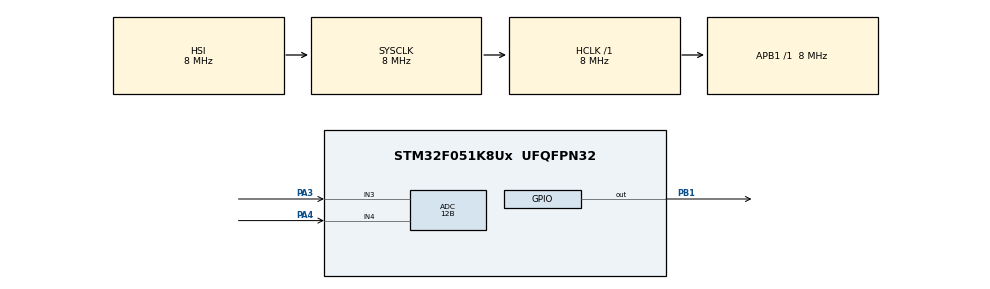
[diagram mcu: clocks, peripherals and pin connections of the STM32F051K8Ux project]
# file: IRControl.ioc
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ADC.ClockPrescaler=ADC_CLOCK_SYNC_PCLK_DIV4
ADC.ContinuousConvMode=DISABLE
ADC.DMAContinuousRequests=DISABLE
ADC.DataAlign=ADC_DATAALIGN_RIGHT
ADC.DiscontinuousConvMode=DISABLE
ADC.EOCSelection=ADC_EOC_SINGLE_CONV
ADC.EnableAnalogWatchDog=false
ADC.ExternalTrigConv=ADC_EXTERNALTRIGCONV_T2_TRGO
ADC.ExternalTrigConvEdge=ADC_EXTERNALTRIGCONVEDGE_RISING
ADC.LowPowerAutoPowerOff=DISABLE
ADC.LowPowerAutoWait=DISABLE
ADC.Overrun=ADC_OVR_DATA_OVERWRITTEN
ADC.Resolution=ADC_RESOLUTION_12B
ADC.SamplingTime=ADC_SAMPLETIME_28CYCLES_5
ADC.ScanConvMode=ADC_SCAN_DIRECTION_FORWARD
Mcu.Family=STM32F0
Mcu.Name=STM32F051K8Ux
Mcu.Package=UFQFPN32
NVIC.ADC1_COMP_IRQn=true\:0\:0\:false\:false\:true\:true
NVIC.TIM6_DAC_IRQn=true\:0\:0\:false\:false\:true\:true
PA13.Mode=Serial_Wire
PA13.Signal=SYS_SWDIO
PA14.Mode=Serial_Wire
PA14.Signal=SYS_SWCLK
PA3.Mode=IN3
PA3.Signal=ADC_IN3
PA4.Mode=IN4
PA4.Signal=ADC_IN4
PB1.Signal=GPIO_Output
ProjectManager.HeapSize=0x200
ProjectManager.StackSize=0x400
ProjectManager.TargetToolchain=EWARM
RCC.AHBFreq_Value=8000000
RCC.APB1Freq_Value=8000000
RCC.APB1TimFreq_Value=8000000
RCC.HCLKFreq_Value=8000000
RCC.PLLMUL=RCC_PLL_MUL9
RCC.SYSCLKFreq_VALUE=8000000
TIM2.TIM_MasterOutputTrigger=TIM_TRGO_UPDATE
VP_TIM2_VS_ClockSourceINT.Mode=Internal
VP_TIM6_VS_ClockSourceINT.Mode=Enable_Timer
board=IRControl

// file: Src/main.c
/**
  ******************************************************************************
  * File Name          : main.c
  * Description        : Main program body
  ******************************************************************************
  ** This notice applies to any and all portions of this file
  * that are not between comment pairs USER CODE BEGIN and
  * USER CODE END. Other portions of this file, whether
  * inserted by the user or by software development tools
  * are owned by their respective copyright owners.
  *
  * COPYRIGHT(c) 2017 STMicroelectronics
  *
  * Redistribution and use in source and binary forms, with or without modification,
  * are permitted provided that the following conditions are met:
  *   1. Redistributions of source code must retain the above copyright notice,
  *      this list of conditions and the following disclaimer.
  *   2. Redistributions in binary form must reproduce the above copyright notice,
  *      this list of conditions and the following disclaimer in the documentation
  *      and/or other materials provided with the distribution.
  *   3. Neither the name of STMicroelectronics nor the names of its contributors
  *      may be used to endorse or promote products derived from this software
  *      without specific prior written permission.
  *
  * THIS SOFTWARE IS PROVIDED BY THE COPYRIGHT HOLDERS AND CONTRIBUTORS "AS IS"
  * AND ANY EXPRESS OR IMPLIED WARRANTIES, INCLUDING, BUT NOT LIMITED TO, THE
  * IMPLIED WARRANTIES OF MERCHANTABILITY AND FITNESS FOR A PARTICULAR PURPOSE ARE
  * DISCLAIMED. IN NO EVENT SHALL THE COPYRIGHT HOLDER OR CONTRIBUTORS BE LIABLE
  * FOR ANY DIRECT, INDIRECT, INCIDENTAL, SPECIAL, EXEMPLARY, OR CONSEQUENTIAL
  * DAMAGES (INCLUDING, BUT NOT LIMITED TO, PROCUREMENT OF SUBSTITUTE GOODS OR
  * SERVICES; LOSS OF USE, DATA, OR PROFITS; OR BUSINESS INTERRUPTION) HOWEVER
  * CAUSED AND ON ANY THEORY OF LIABILITY, WHETHER IN CONTRACT, STRICT LIABILITY,
  * OR TORT (INCLUDING NEGLIGENCE OR OTHERWISE) ARISING IN ANY WAY OUT OF THE USE
  * OF THIS SOFTWARE, EVEN IF ADVISED OF THE POSSIBILITY OF SUCH DAMAGE.
  *
  ******************************************************************************
  */

#include "main.h"
#include "stm32f0xx_hal.h"

/* USER CODE BEGIN Includes */
#define ADC_BUF_SIZE   ((uint32_t)  128)   /* Size of array aADCxConvertedData[] */

/* USER CODE END Includes */

ADC_HandleTypeDef hadc;

TIM_HandleTypeDef htim2;
TIM_HandleTypeDef htim6;

/* USER CODE BEGIN PV */
/* Private variables ---------------------------------------------------------*/
uint16_t Counts[NumCount];
uint8_t  flag_ovf;
static uint16_t   DataADCCh3[ADC_BUF_SIZE];
static uint16_t   DataADCCh4[ADC_BUF_SIZE];
//__IO uint16_t uhADCxConvertedValue = 0;
uint8_t IndADC3=0,IndADC4=0;

/* USER CODE END PV */

void SystemClock_Config(void);
static void MX_GPIO_Init(void);
static void MX_ADC_Init(void);
static void MX_TIM6_Init(void);
static void MX_TIM2_Init(void);

/* USER CODE BEGIN PFP */
/* Private function prototypes -----------------------------------------------*/
void TimeControlInit(void);
/* USER CODE END PFP */

int main(void)
{

  /* MCU Configuration----------------------------------------------------------*/

  /* Reset of all peripherals, Initializes the Flash interface and the Systick. */
  HAL_Init();

  /* Configure the system clock */
  SystemClock_Config();

  /* Initialize all configured peripherals */
  MX_GPIO_Init();
  MX_ADC_Init();
  MX_TIM6_Init();
  MX_TIM2_Init();

  /* USER CODE BEGIN 2 */
  if (HAL_ADCEx_Calibration_Start(&hadc) != HAL_OK) {Error_Handler();}

  TimeControlInit();
  set_time(TIME_LAMP,1);

  if (HAL_ADC_Start_IT(&hadc) != HAL_OK)
  {
    /* Start Conversation Error */
    Error_Handler();
  }

  /*##-3- TIM counter enable ################################################*/
  if (HAL_TIM_Base_Start(&htim2) != HAL_OK)
  {
    /* Counter Enable Error */
    Error_Handler();
  }

  /* USER CODE END 2 */

  /* Infinite loop */
  while (1)
  {

  /* USER CODE BEGIN 3 */

    if(time_ovf(TIME_LAMP)){
      set_time(TIME_LAMP,503);
      LampToggle();
      if(ReadLampON()) IndADC3=0;
    }
  }
  /* USER CODE END 3 */

}

/** System Clock Configuration
*/
void SystemClock_Config(void)
{

  RCC_OscInitTypeDef RCC_OscInitStruct;
  RCC_ClkInitTypeDef RCC_ClkInitStruct;

    /**Initializes the CPU, AHB and APB busses clocks
    */
  RCC_OscInitStruct.OscillatorType = RCC_OSCILLATORTYPE_HSI;
  RCC_OscInitStruct.HSIState = RCC_HSI_ON;
  RCC_OscInitStruct.HSICalibrationValue = 16;
  RCC_OscInitStruct.PLL.PLLState = RCC_PLL_NONE;
  if (HAL_RCC_OscConfig(&RCC_OscInitStruct) != HAL_OK)
  {
    _Error_Handler(__FILE__, __LINE__);
  }

    /**Initializes the CPU, AHB and APB busses clocks
    */
  RCC_ClkInitStruct.ClockType = RCC_CLOCKTYPE_HCLK|RCC_CLOCKTYPE_SYSCLK
                              |RCC_CLOCKTYPE_PCLK1;
  RCC_ClkInitStruct.SYSCLKSource = RCC_SYSCLKSOURCE_HSI;
  RCC_ClkInitStruct.AHBCLKDivider = RCC_SYSCLK_DIV1;
  RCC_ClkInitStruct.APB1CLKDivider = RCC_HCLK_DIV1;

  if (HAL_RCC_ClockConfig(&RCC_ClkInitStruct, FLASH_LATENCY_0) != HAL_OK)
  {
    _Error_Handler(__FILE__, __LINE__);
  }

    /**Configure the Systick interrupt time
    */
  HAL_SYSTICK_Config(HAL_RCC_GetHCLKFreq()/1000);

    /**Configure the Systick
    */
  HAL_SYSTICK_CLKSourceConfig(SYSTICK_CLKSOURCE_HCLK);

  /* SysTick_IRQn interrupt configuration */
  HAL_NVIC_SetPriority(SysTick_IRQn, 0, 0);
}

/* ADC init function */
static void MX_ADC_Init(void)
{

  ADC_ChannelConfTypeDef sConfig;

    /**Configure the global features of the ADC (Clock, Resolution, Data Alignment and number of conversion)
    */
  hadc.Instance = ADC1;
  hadc.Init.ClockPrescaler = ADC_CLOCK_SYNC_PCLK_DIV4;
  hadc.Init.Resolution = ADC_RESOLUTION_12B;
  hadc.Init.DataAlign = ADC_DATAALIGN_RIGHT;
  hadc.Init.ScanConvMode = ADC_SCAN_DIRECTION_FORWARD;
  hadc.Init.EOCSelection = ADC_EOC_SINGLE_CONV;
  hadc.Init.LowPowerAutoWait = DISABLE;
  hadc.Init.LowPowerAutoPowerOff = DISABLE;
  hadc.Init.ContinuousConvMode = DISABLE;
  hadc.Init.DiscontinuousConvMode = DISABLE;
  hadc.Init.ExternalTrigConv = ADC_EXTERNALTRIGCONV_T2_TRGO;
  hadc.Init.ExternalTrigConvEdge = ADC_EXTERNALTRIGCONVEDGE_RISING;
  hadc.Init.DMAContinuousRequests = DISABLE;
  hadc.Init.Overrun = ADC_OVR_DATA_OVERWRITTEN;
  if (HAL_ADC_Init(&hadc) != HAL_OK)
  {
    _Error_Handler(__FILE__, __LINE__);
  }

    /**Configure for the selected ADC regular channel to be converted.
    */
  sConfig.Channel = ADC_CHANNEL_3;
  sConfig.Rank = ADC_RANK_CHANNEL_NUMBER;
  sConfig.SamplingTime = ADC_SAMPLETIME_28CYCLES_5;
  if (HAL_ADC_ConfigChannel(&hadc, &sConfig) != HAL_OK)
  {
    _Error_Handler(__FILE__, __LINE__);
  }

    /**Configure for the selected ADC regular channel to be converted.
    */
  sConfig.Channel = ADC_CHANNEL_4;
  if (HAL_ADC_ConfigChannel(&hadc, &sConfig) != HAL_OK)
  {
    _Error_Handler(__FILE__, __LINE__);
  }

}

/* TIM2 init function */
static void MX_TIM2_Init(void)
{

  TIM_ClockConfigTypeDef sClockSourceConfig;
  TIM_MasterConfigTypeDef sMasterConfig;

  htim2.Instance = TIM2;
  htim2.Init.Prescaler = 0;
  htim2.Init.CounterMode = TIM_COUNTERMODE_UP;
  htim2.Init.Period = 0;
  htim2.Init.ClockDivision = TIM_CLOCKDIVISION_DIV1;
  htim2.Init.AutoReloadPreload = TIM_AUTORELOAD_PRELOAD_DISABLE;
  if (HAL_TIM_Base_Init(&htim2) != HAL_OK)
  {
    _Error_Handler(__FILE__, __LINE__);
  }

  sClockSourceConfig.ClockSource = TIM_CLOCKSOURCE_INTERNAL;
  if (HAL_TIM_ConfigClockSource(&htim2, &sClockSourceConfig) != HAL_OK)
  {
    _Error_Handler(__FILE__, __LINE__);
  }

  sMasterConfig.MasterOutputTrigger = TIM_TRGO_UPDATE;
  sMasterConfig.MasterSlaveMode = TIM_MASTERSLAVEMODE_DISABLE;
  if (HAL_TIMEx_MasterConfigSynchronization(&htim2, &sMasterConfig) != HAL_OK)
  {
    _Error_Handler(__FILE__, __LINE__);
  }

}

/* TIM6 init function */
static void MX_TIM6_Init(void)
{

  TIM_MasterConfigTypeDef sMasterConfig;

  htim6.Instance = TIM6;
  htim6.Init.Prescaler = 0;
  htim6.Init.CounterMode = TIM_COUNTERMODE_UP;
  htim6.Init.Period = 0;
  htim6.Init.AutoReloadPreload = TIM_AUTORELOAD_PRELOAD_DISABLE;
  if (HAL_TIM_Base_Init(&htim6) != HAL_OK)
  {
    _Error_Handler(__FILE__, __LINE__);
  }

  sMasterConfig.MasterOutputTrigger = TIM_TRGO_RESET;
  sMasterConfig.MasterSlaveMode = TIM_MASTERSLAVEMODE_DISABLE;
  if (HAL_TIMEx_MasterConfigSynchronization(&htim6, &sMasterConfig) != HAL_OK)
  {
    _Error_Handler(__FILE__, __LINE__);
  }

}

/** Configure pins as
        * Analog
        * Input
        * Output
        * EVENT_OUT
        * EXTI
*/
static void MX_GPIO_Init(void)
{

  GPIO_InitTypeDef GPIO_InitStruct;

  /* GPIO Ports Clock Enable */
  __HAL_RCC_GPIOA_CLK_ENABLE();
  __HAL_RCC_GPIOB_CLK_ENABLE();

  /*Configure GPIO pin Output Level */
  HAL_GPIO_WritePin(GPIOB, GPIO_PIN_1, GPIO_PIN_RESET);

  /*Configure GPIO pin : PB1 */
  GPIO_InitStruct.Pin = GPIO_PIN_1;
  GPIO_InitStruct.Mode = GPIO_MODE_OUTPUT_PP;
  GPIO_InitStruct.Pull = GPIO_NOPULL;
  GPIO_InitStruct.Speed = GPIO_SPEED_FREQ_LOW;
  HAL_GPIO_Init(GPIOB, &GPIO_InitStruct);

}

/* USER CODE BEGIN 4 */
void TimeControlInit(void)
{
  uint8_t Ind;
  for(Ind=0;Ind<NumCount;Ind++) Counts[Ind]=0;
  flag_ovf=0;
  htim6.Init.Period = 100;//1ms
  htim6.Init.Prescaler = HAL_RCC_GetHCLKFreq()/100000;
  htim6.Init.ClockDivision = 0;
  htim6.Init.CounterMode = TIM_COUNTERMODE_DOWN;
  HAL_TIM_Base_Init(&htim6);
  __HAL_TIM_ENABLE_IT(&htim6,TIM_IT_UPDATE);
  __HAL_TIM_ENABLE(&htim6);

  //ADC TRGO
  htim2.Init.Period = 1000;//10ms
  htim2.Init.Prescaler = HAL_RCC_GetHCLKFreq()/100000;
  HAL_TIM_Base_Init(&htim2);
  //__HAL_TIM_ENABLE(&htim2);

}

void HAL_ADC_ConvCpltCallback(ADC_HandleTypeDef *AdcHandle)
{
  if(AdcHandle->Instance->CHSELR == (1<<3)){
    DataADCCh3[IndADC3] = HAL_ADC_GetValue(&hadc);
    if(IndADC3<(ADC_BUF_SIZE-1))IndADC3++;
  }
  if(AdcHandle->Instance->CHSELR == (1<<4)){
    DataADCCh4[IndADC4] = HAL_ADC_GetValue(&hadc);
    if(IndADC4<(ADC_BUF_SIZE-1))IndADC4++;
  }
}

void HAL_TIM_PeriodElapsedCallback(TIM_HandleTypeDef *htim)
{
  for(uint8_t temp=0;temp<NumCount;temp++)
   if(Counts[temp]>0)
   {if(Counts[temp]==1)
     flag_ovf|=(1<<temp);
    Counts[temp]--;
   }

}
/* USER CODE END 4 */

void _Error_Handler(char * file, int line)
{
  while(1)
  {
  }
}

/************************ (C) COPYRIGHT STMicroelectronics *****END OF FILE****/
